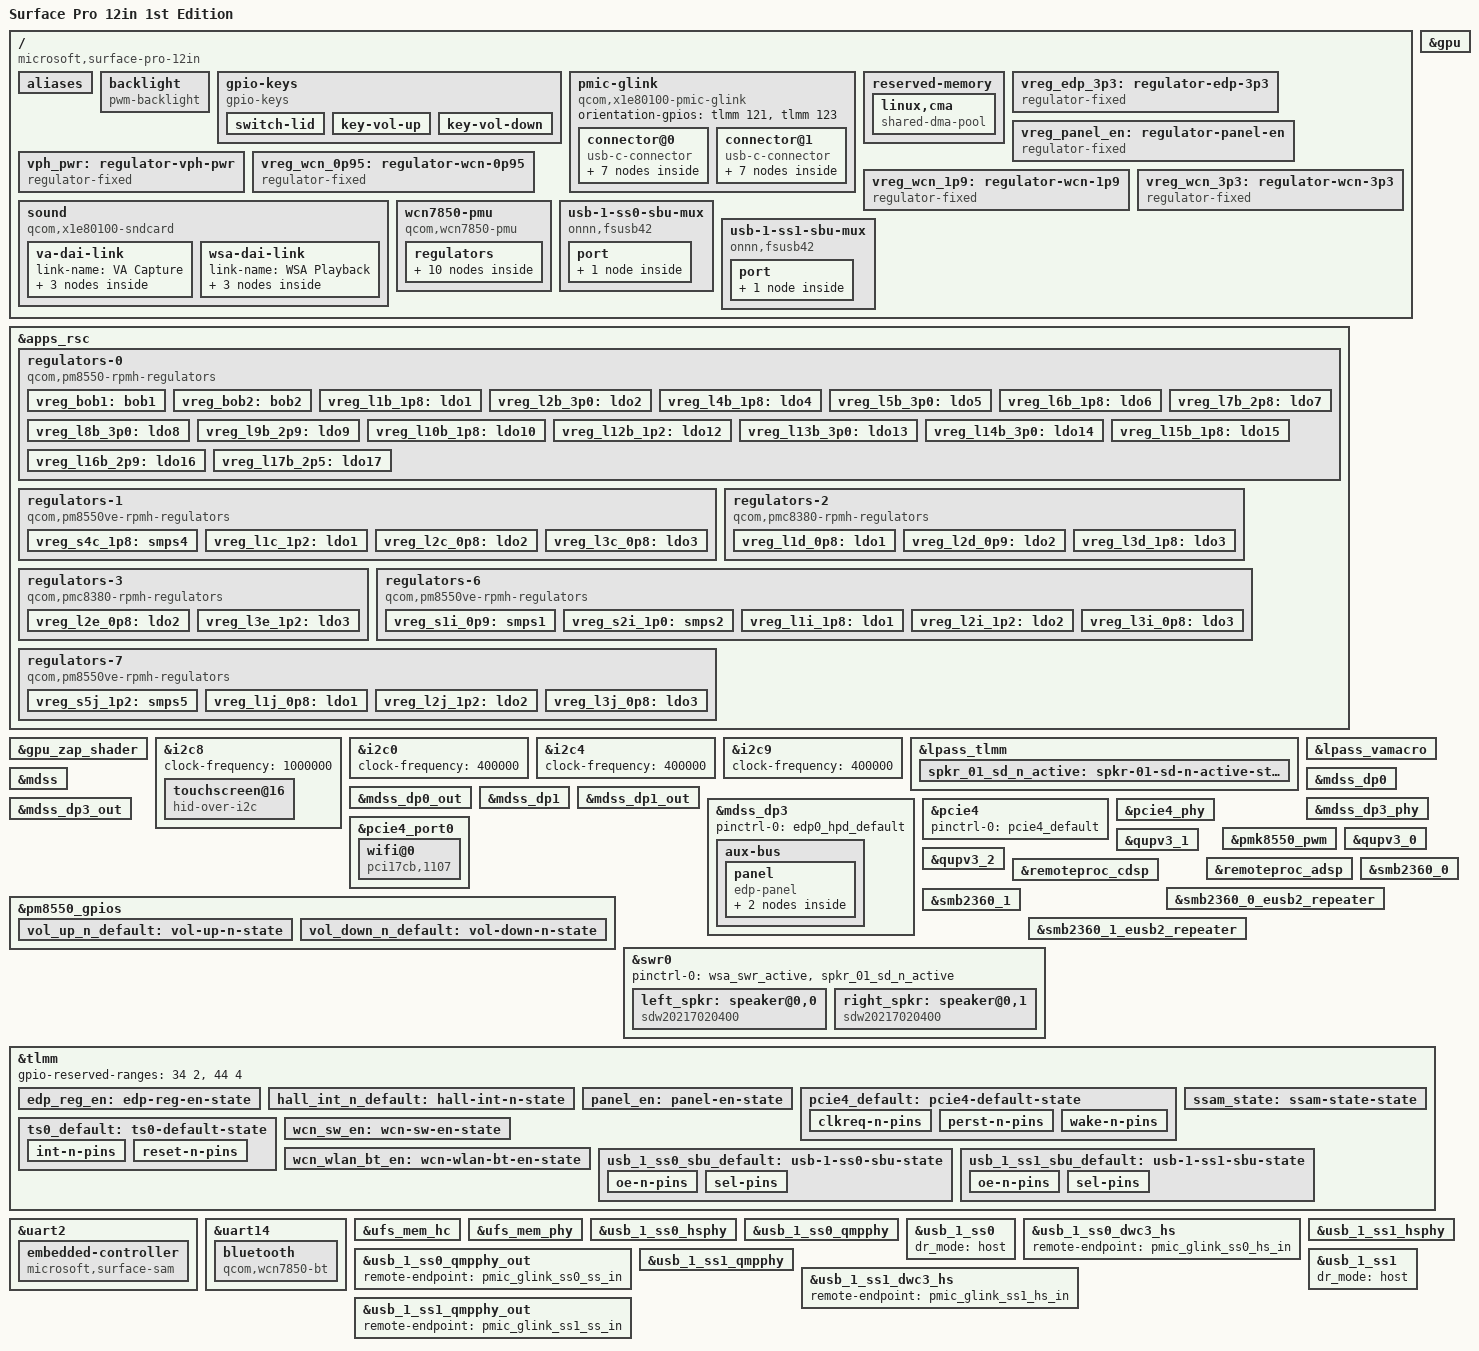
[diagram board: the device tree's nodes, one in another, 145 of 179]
// SPDX-License-Identifier: BSD-3-Clause
/*
 * Copyright (c) 2023 Qualcomm Innovation Center, Inc. All rights reserved.
 * Copyright (c) 2024, Linaro Limited
 * Copyright (c) 2025, Jens Glathe
 * Copyright (c) 2025, Harrison Vanderbyl
 */

/dts-v1/;

#include <dt-bindings/gpio/gpio.h>
#include <dt-bindings/input/gpio-keys.h>
#include <dt-bindings/input/input.h>
#include <dt-bindings/pinctrl/qcom,pmic-gpio.h>
#include <dt-bindings/regulator/qcom,rpmh-regulator.h>
#include <dt-bindings/clock/qcom,x1e80100-tcsr.h>

#include "purwa.dtsi"
#include "hamoa-pmics.dtsi"

/delete-node/ &pmc8380_6;
/delete-node/ &pmc8380_6_thermal;

/ {
	model = "Surface Pro 12in 1st Edition";
	compatible = "microsoft,surface-pro-12in", "qcom,x1p42100";
	chassis-type = "tablet";

	aliases {
		serial0 = &uart2;
		serial1 = &uart14;
	};

	backlight: backlight {
		compatible = "pwm-backlight";
		pwms = <&pmk8550_pwm 0 5000000>;

		power-supply = <&vreg_edp_3p3>;
	};

	gpio-keys {
		compatible = "gpio-keys";

		pinctrl-0 = <&hall_int_n_default>, <&vol_up_n_default>, <&vol_down_n_default>;
		pinctrl-names = "default";

		switch-lid {
			gpios = <&tlmm 2 GPIO_ACTIVE_LOW>;
			linux,input-type = <EV_SW>;
			linux,code = <SW_LID>;
			wakeup-source;
			wakeup-event-action = <EV_ACT_DEASSERTED>;
		};

		key-vol-up {
			gpios = <&pm8550_gpios 8 GPIO_ACTIVE_LOW>;
			linux,code = <KEY_VOLUMEUP>;
			debounce-interval = <15>;
			linux,can-disable;
			wakeup-source;
		};

		key-vol-down {
			gpios = <&pm8550_gpios 6 GPIO_ACTIVE_LOW>;
			linux,code = <KEY_VOLUMEDOWN>;
			debounce-interval = <15>;
			linux,can-disable;
			wakeup-source;
		};
	};

	pmic-glink {
		compatible = "qcom,x1e80100-pmic-glink",
			     "qcom,sm8550-pmic-glink",
			     "qcom,pmic-glink";
		orientation-gpios = <&tlmm 121 GPIO_ACTIVE_HIGH>,
				    <&tlmm 123 GPIO_ACTIVE_HIGH>;
		#address-cells = <1>;
		#size-cells = <0>;

		/* Right-side upper port */
		connector@0 {
			compatible = "usb-c-connector";
			reg = <0>;
			power-role = "dual";
			data-role = "dual";

			ports {
				#address-cells = <1>;
				#size-cells = <0>;

				port@0 {
					reg = <0>;

					pmic_glink_ss0_hs_in: endpoint {
						remote-endpoint = <&usb_1_ss0_dwc3_hs>;
					};
				};

				port@1 {
					reg = <1>;

					pmic_glink_ss0_ss_in: endpoint {
						remote-endpoint = <&usb_1_ss0_qmpphy_out>;
					};
				};

				port@2 {
					reg = <2>;

					pmic_glink_ss0_sbu: endpoint {
						remote-endpoint = <&usb_1_ss0_sbu_mux>;
					};
				};
			};
		};

		/* Right-side lower port */
		connector@1 {
			compatible = "usb-c-connector";
			reg = <1>;
			power-role = "dual";
			data-role = "dual";

			ports {
				#address-cells = <1>;
				#size-cells = <0>;

				port@0 {
					reg = <0>;

					pmic_glink_ss1_hs_in: endpoint {
						remote-endpoint = <&usb_1_ss1_dwc3_hs>;
					};
				};

				port@1 {
					reg = <1>;

					pmic_glink_ss1_ss_in: endpoint {
						remote-endpoint = <&usb_1_ss1_qmpphy_out>;
					};
				};

				port@2 {
					reg = <2>;

					pmic_glink_ss1_sbu: endpoint {
						remote-endpoint = <&usb_1_ss1_sbu_mux>;
					};
				};
			};
		};
	};

	reserved-memory {
		linux,cma {
			compatible = "shared-dma-pool";
			size = <0x0 0x20000000>;
			reusable;
			linux,cma-default;
		};
	};

	vreg_edp_3p3: regulator-edp-3p3 {
		compatible = "regulator-fixed";

		regulator-name = "VREG_EDP_3P3";
		regulator-min-microvolt = <3300000>;
		regulator-max-microvolt = <3300000>;

		gpio = <&tlmm 70 GPIO_ACTIVE_HIGH>;
		enable-active-high;

		pinctrl-0 = <&edp_reg_en>;
		pinctrl-names = "default";

		regulator-boot-on;
		vin-supply = <&vreg_panel_en>;
	};

	vreg_panel_en: regulator-panel-en {
		compatible = "regulator-fixed";

		regulator-name = "VREG_PANEL_EN";
		regulator-min-microvolt = <3300000>;
		regulator-max-microvolt = <3300000>;

		gpio = <&tlmm 29 GPIO_ACTIVE_HIGH>;
		enable-active-high;

		regulator-enable-ramp-delay = <150000>;

		pinctrl-0 = <&panel_en>;
		pinctrl-names = "default";

		regulator-boot-on;
	};

	vph_pwr: regulator-vph-pwr {
		compatible = "regulator-fixed";

		regulator-name = "vph_pwr";
		regulator-min-microvolt = <3700000>;
		regulator-max-microvolt = <3700000>;
	};

	vreg_wcn_0p95: regulator-wcn-0p95 {
		compatible = "regulator-fixed";

		regulator-name = "VREG_WCN_0P95";
		regulator-min-microvolt = <950000>;
		regulator-max-microvolt = <950000>;

		vin-supply = <&vreg_wcn_3p3>;
	};

	vreg_wcn_1p9: regulator-wcn-1p9 {
		compatible = "regulator-fixed";

		regulator-name = "VREG_WCN_1P9";
		regulator-min-microvolt = <1900000>;
		regulator-max-microvolt = <1900000>;

		vin-supply = <&vreg_wcn_3p3>;
	};

	vreg_wcn_3p3: regulator-wcn-3p3 {
		compatible = "regulator-fixed";

		regulator-name = "VREG_WCN_3P3";
		regulator-min-microvolt = <3300000>;
		regulator-max-microvolt = <3300000>;

		gpio = <&tlmm 214 GPIO_ACTIVE_HIGH>;
		enable-active-high;

		pinctrl-0 = <&wcn_sw_en>;
		pinctrl-names = "default";
	};

	sound {
		compatible = "qcom,x1e80100-sndcard";
		model = "X1P42100-Microsoft-Surface-Pro-12in";
		audio-routing = "SpkrLeft IN", "WSA WSA_SPK1 OUT",
				"SpkrRight IN", "WSA WSA_SPK2 OUT",
				"VA DMIC0", "vdd-micb",
				"VA DMIC1", "vdd-micb";

		va-dai-link {
			link-name = "VA Capture";

			codec {
				sound-dai = <&lpass_vamacro 0>;
			};

			cpu {
				sound-dai = <&q6apmbedai VA_CODEC_DMA_TX_0>;
			};

			platform {
				sound-dai = <&q6apm>;
			};
		};

		wsa-dai-link {
			link-name = "WSA Playback";

			codec {
				sound-dai = <&left_spkr>, <&right_spkr>,
					    <&swr0 0>, <&lpass_wsamacro 0>;
			};

			cpu {
				sound-dai = <&q6apmbedai WSA_CODEC_DMA_RX_0>;
			};

			platform {
				sound-dai = <&q6apm>;
			};
		};
	};

	wcn7850-pmu {
		compatible = "qcom,wcn7850-pmu";

		vdd-supply = <&vreg_wcn_0p95>;
		vddio-supply = <&vreg_l15b_1p8>;
		vddaon-supply = <&vreg_wcn_0p95>;
		vdddig-supply = <&vreg_wcn_0p95>;
		vddrfa1p2-supply = <&vreg_wcn_1p9>;
		vddrfa1p8-supply = <&vreg_wcn_1p9>;

		wlan-enable-gpios = <&tlmm 117 GPIO_ACTIVE_HIGH>;
		bt-enable-gpios = <&tlmm 116 GPIO_ACTIVE_HIGH>;

		pinctrl-0 = <&wcn_wlan_bt_en>;
		pinctrl-names = "default";

		regulators {
			vreg_pmu_rfa_cmn: ldo0 {
				regulator-name = "vreg_pmu_rfa_cmn";
			};

			vreg_pmu_aon_0p59: ldo1 {
				regulator-name = "vreg_pmu_aon_0p59";
			};

			vreg_pmu_wlcx_0p8: ldo2 {
				regulator-name = "vreg_pmu_wlcx_0p8";
			};

			vreg_pmu_wlmx_0p85: ldo3 {
				regulator-name = "vreg_pmu_wlmx_0p85";
			};

			vreg_pmu_btcmx_0p85: ldo4 {
				regulator-name = "vreg_pmu_btcmx_0p85";
			};

			vreg_pmu_rfa_0p8: ldo5 {
				regulator-name = "vreg_pmu_rfa_0p8";
			};

			vreg_pmu_rfa_1p2: ldo6 {
				regulator-name = "vreg_pmu_rfa_1p2";
			};

			vreg_pmu_rfa_1p8: ldo7 {
				regulator-name = "vreg_pmu_rfa_1p8";
			};

			vreg_pmu_pcie_0p9: ldo8 {
				regulator-name = "vreg_pmu_pcie_0p9";
			};

			vreg_pmu_pcie_1p8: ldo9 {
				regulator-name = "vreg_pmu_pcie_1p8";
			};
		};
	};

	usb-1-ss0-sbu-mux {
		compatible = "onnn,fsusb42", "gpio-sbu-mux";

		enable-gpios = <&tlmm 168 GPIO_ACTIVE_LOW>;
		select-gpios = <&tlmm 167 GPIO_ACTIVE_HIGH>;

		pinctrl-0 = <&usb_1_ss0_sbu_default>;
		pinctrl-names = "default";

		mode-switch;
		orientation-switch;

		port {
			usb_1_ss0_sbu_mux: endpoint {
				remote-endpoint = <&pmic_glink_ss0_sbu>;
			};
		};
	};

	usb-1-ss1-sbu-mux {
		compatible = "onnn,fsusb42", "gpio-sbu-mux";

		enable-gpios = <&tlmm 179 GPIO_ACTIVE_LOW>;
		select-gpios = <&tlmm 178 GPIO_ACTIVE_HIGH>;

		pinctrl-0 = <&usb_1_ss1_sbu_default>;
		pinctrl-names = "default";

		mode-switch;
		orientation-switch;

		port {
			usb_1_ss1_sbu_mux: endpoint {
				remote-endpoint = <&pmic_glink_ss1_sbu>;
			};
		};
	};
};

&apps_rsc {
	regulators-0 {
		compatible = "qcom,pm8550-rpmh-regulators";
		qcom,pmic-id = "b";

		vdd-bob1-supply = <&vph_pwr>;
		vdd-bob2-supply = <&vph_pwr>;
		vdd-l1-l4-l10-supply = <&vreg_s4c_1p8>;
		vdd-l2-l13-l14-supply = <&vreg_bob1>;
		vdd-l5-l16-supply = <&vreg_bob1>;
		vdd-l6-l7-supply = <&vreg_bob2>;
		vdd-l8-l9-supply = <&vreg_bob1>;
		vdd-l12-supply = <&vreg_s5j_1p2>;
		vdd-l15-supply = <&vreg_s4c_1p8>;
		vdd-l17-supply = <&vreg_bob2>;

		vreg_bob1: bob1 {
			regulator-name = "vreg_bob1";
			regulator-min-microvolt = <3008000>;
			regulator-max-microvolt = <3960000>;
			regulator-initial-mode = <RPMH_REGULATOR_MODE_HPM>;
		};

		vreg_bob2: bob2 {
			regulator-name = "vreg_bob2";
			regulator-min-microvolt = <2504000>;
			regulator-max-microvolt = <3008000>;
			regulator-initial-mode = <RPMH_REGULATOR_MODE_HPM>;
		};

		vreg_l1b_1p8: ldo1 {
			regulator-name = "vreg_l1b_1p8";
			regulator-min-microvolt = <1800000>;
			regulator-max-microvolt = <1800000>;
			regulator-initial-mode = <RPMH_REGULATOR_MODE_HPM>;
		};

		vreg_l2b_3p0: ldo2 {
			regulator-name = "vreg_l2b_3p0";
			regulator-min-microvolt = <3072000>;
			regulator-max-microvolt = <3100000>;
			regulator-initial-mode = <RPMH_REGULATOR_MODE_HPM>;
		};

		vreg_l4b_1p8: ldo4 {
			regulator-name = "vreg_l4b_1p8";
			regulator-min-microvolt = <1800000>;
			regulator-max-microvolt = <1800000>;
			regulator-initial-mode = <RPMH_REGULATOR_MODE_HPM>;
		};

		vreg_l5b_3p0: ldo5 {
			regulator-name = "vreg_l5b_3p0";
			regulator-min-microvolt = <3000000>;
			regulator-max-microvolt = <3000000>;
			regulator-initial-mode = <RPMH_REGULATOR_MODE_HPM>;
		};

		vreg_l6b_1p8: ldo6 {
			regulator-name = "vreg_l6b_1p8";
			regulator-min-microvolt = <1800000>;
			regulator-max-microvolt = <2960000>;
			regulator-initial-mode = <RPMH_REGULATOR_MODE_HPM>;
		};

		vreg_l7b_2p8: ldo7 {
			regulator-name = "vreg_l7b_2p8";
			regulator-min-microvolt = <2800000>;
			regulator-max-microvolt = <2800000>;
			regulator-initial-mode = <RPMH_REGULATOR_MODE_HPM>;
			regulator-always-on;
		};

		vreg_l8b_3p0: ldo8 {
			regulator-name = "vreg_l8b_3p0";
			regulator-min-microvolt = <3072000>;
			regulator-max-microvolt = <3072000>;
			regulator-initial-mode = <RPMH_REGULATOR_MODE_HPM>;
		};

		vreg_l9b_2p9: ldo9 {
			regulator-name = "vreg_l9b_2p9";
			regulator-min-microvolt = <2960000>;
			regulator-max-microvolt = <2960000>;
			regulator-initial-mode = <RPMH_REGULATOR_MODE_HPM>;
		};

		vreg_l10b_1p8: ldo10 {
			regulator-name = "vreg_l10b_1p8";
			regulator-min-microvolt = <1800000>;
			regulator-max-microvolt = <1800000>;
			regulator-initial-mode = <RPMH_REGULATOR_MODE_HPM>;
		};

		vreg_l12b_1p2: ldo12 {
			regulator-name = "vreg_l12b_1p2";
			regulator-min-microvolt = <1200000>;
			regulator-max-microvolt = <1200000>;
			regulator-initial-mode = <RPMH_REGULATOR_MODE_HPM>;
		};

		vreg_l13b_3p0: ldo13 {
			regulator-name = "vreg_l13b_3p0";
			regulator-min-microvolt = <3072000>;
			regulator-max-microvolt = <3100000>;
			regulator-initial-mode = <RPMH_REGULATOR_MODE_HPM>;
		};

		vreg_l14b_3p0: ldo14 {
			regulator-name = "vreg_l14b_3p0";
			regulator-min-microvolt = <3072000>;
			regulator-max-microvolt = <3072000>;
			regulator-initial-mode = <RPMH_REGULATOR_MODE_HPM>;
		};

		vreg_l15b_1p8: ldo15 {
			regulator-name = "vreg_l15b_1p8";
			regulator-min-microvolt = <1800000>;
			regulator-max-microvolt = <1800000>;
			regulator-initial-mode = <RPMH_REGULATOR_MODE_HPM>;
		};

		vreg_l16b_2p9: ldo16 {
			regulator-name = "vreg_l16b_2p9";
			regulator-min-microvolt = <2900000>;
			regulator-max-microvolt = <2912000>;
			regulator-initial-mode = <RPMH_REGULATOR_MODE_HPM>;
			regulator-allow-set-load;
			regulator-allowed-modes = <RPMH_REGULATOR_MODE_LPM
						   RPMH_REGULATOR_MODE_HPM>;
		};

		vreg_l17b_2p5: ldo17 {
			regulator-name = "vreg_l17b_2p5";
			regulator-min-microvolt = <2504000>;
			regulator-max-microvolt = <2504000>;
			regulator-initial-mode = <RPMH_REGULATOR_MODE_HPM>;
			regulator-allow-set-load;
			regulator-allowed-modes = <RPMH_REGULATOR_MODE_LPM
						   RPMH_REGULATOR_MODE_HPM>;
		};
	};

	regulators-1 {
		compatible = "qcom,pm8550ve-rpmh-regulators";
		qcom,pmic-id = "c";

		vdd-l1-supply = <&vreg_s5j_1p2>;
		vdd-s4-supply = <&vph_pwr>;

		vreg_s4c_1p8: smps4 {
			regulator-name = "vreg_s4c_1p8";
			regulator-min-microvolt = <1856000>;
			regulator-max-microvolt = <2000000>;
			regulator-initial-mode = <RPMH_REGULATOR_MODE_HPM>;
		};

		vreg_l1c_1p2: ldo1 {
			regulator-name = "vreg_l1c_1p2";
			regulator-min-microvolt = <1200000>;
			regulator-max-microvolt = <1200000>;
			regulator-initial-mode = <RPMH_REGULATOR_MODE_HPM>;
		};

		vreg_l2c_0p8: ldo2 {
			regulator-name = "vreg_l2c_0p8";
			regulator-min-microvolt = <880000>;
			regulator-max-microvolt = <920000>;
			regulator-initial-mode = <RPMH_REGULATOR_MODE_HPM>;
		};

		vreg_l3c_0p8: ldo3 {
			regulator-name = "vreg_l3c_0p8";
			regulator-min-microvolt = <880000>;
			regulator-max-microvolt = <920000>;
			regulator-initial-mode = <RPMH_REGULATOR_MODE_HPM>;
		};
	};

	regulators-2 {
		compatible = "qcom,pmc8380-rpmh-regulators";
		qcom,pmic-id = "d";

		vdd-l3-supply = <&vreg_s4c_1p8>;
		vdd-s1-supply = <&vph_pwr>;

		vreg_l1d_0p8: ldo1 {
			regulator-name = "vreg_l1d_0p8";
			regulator-min-microvolt = <880000>;
			regulator-max-microvolt = <920000>;
			regulator-initial-mode = <RPMH_REGULATOR_MODE_HPM>;
		};

		vreg_l2d_0p9: ldo2 {
			regulator-name = "vreg_l2d_0p9";
			regulator-min-microvolt = <912000>;
			regulator-max-microvolt = <920000>;
			regulator-initial-mode = <RPMH_REGULATOR_MODE_HPM>;
		};

		vreg_l3d_1p8: ldo3 {
			regulator-name = "vreg_l3d_1p8";
			regulator-min-microvolt = <1800000>;
			regulator-max-microvolt = <1800000>;
			regulator-initial-mode = <RPMH_REGULATOR_MODE_HPM>;
		};
	};

	regulators-3 {
		compatible = "qcom,pmc8380-rpmh-regulators";
		qcom,pmic-id = "e";

		vdd-l3-supply = <&vreg_s5j_1p2>;

		vreg_l2e_0p8: ldo2 {
			regulator-name = "vreg_l2e_0p8";
			regulator-min-microvolt = <880000>;
			regulator-max-microvolt = <880000>;
			regulator-initial-mode = <RPMH_REGULATOR_MODE_HPM>;
		};

		vreg_l3e_1p2: ldo3 {
			regulator-name = "vreg_l3e_1p2";
			regulator-min-microvolt = <1200000>;
			regulator-max-microvolt = <1200000>;
			regulator-initial-mode = <RPMH_REGULATOR_MODE_HPM>;
			regulator-allow-set-load;
			regulator-allowed-modes = <RPMH_REGULATOR_MODE_LPM
						   RPMH_REGULATOR_MODE_HPM>;
		};
	};

	regulators-6 {
		compatible = "qcom,pm8550ve-rpmh-regulators";
		qcom,pmic-id = "i";

		vdd-l1-supply = <&vreg_s4c_1p8>;
		vdd-l2-supply = <&vreg_s5j_1p2>;
		vdd-s1-supply = <&vph_pwr>;
		vdd-s2-supply = <&vph_pwr>;

		vreg_s1i_0p9: smps1 {
			regulator-name = "vreg_s1i_0p9";
			regulator-min-microvolt = <900000>;
			regulator-max-microvolt = <920000>;
			regulator-initial-mode = <RPMH_REGULATOR_MODE_HPM>;
		};

		vreg_s2i_1p0: smps2 {
			regulator-name = "vreg_s2i_1p0";
			regulator-min-microvolt = <1000000>;
			regulator-max-microvolt = <1100000>;
			regulator-initial-mode = <RPMH_REGULATOR_MODE_HPM>;
		};

		vreg_l1i_1p8: ldo1 {
			regulator-name = "vreg_l1i_1p8";
			regulator-min-microvolt = <1800000>;
			regulator-max-microvolt = <1800000>;
			regulator-initial-mode = <RPMH_REGULATOR_MODE_HPM>;
		};

		vreg_l2i_1p2: ldo2 {
			regulator-name = "vreg_l2i_1p2";
			regulator-min-microvolt = <1200000>;
			regulator-max-microvolt = <1200000>;
			regulator-initial-mode = <RPMH_REGULATOR_MODE_HPM>;
			regulator-allow-set-load;
			regulator-allowed-modes = <RPMH_REGULATOR_MODE_LPM
						   RPMH_REGULATOR_MODE_HPM>;
		};

		vreg_l3i_0p8: ldo3 {
			regulator-name = "vreg_l3i_0p8";
			regulator-min-microvolt = <880000>;
			regulator-max-microvolt = <880000>;
			regulator-initial-mode = <RPMH_REGULATOR_MODE_HPM>;
			regulator-allow-set-load;
			regulator-allowed-modes = <RPMH_REGULATOR_MODE_LPM
						   RPMH_REGULATOR_MODE_HPM>;
		};
	};

	regulators-7 {
		compatible = "qcom,pm8550ve-rpmh-regulators";
		qcom,pmic-id = "j";

		vdd-l2-supply = <&vreg_s5j_1p2>;
		vdd-s5-supply = <&vph_pwr>;

		vreg_s5j_1p2: smps5 {
			regulator-name = "vreg_s5j_1p2";
			regulator-min-microvolt = <1256000>;
			regulator-max-microvolt = <1304000>;
			regulator-initial-mode = <RPMH_REGULATOR_MODE_HPM>;
		};

		vreg_l1j_0p8: ldo1 {
			regulator-name = "vreg_l1j_0p8";
			regulator-min-microvolt = <880000>;
			regulator-max-microvolt = <920000>;
			regulator-initial-mode = <RPMH_REGULATOR_MODE_HPM>;
		};

		vreg_l2j_1p2: ldo2 {
			regulator-name = "vreg_l2j_1p2";
			regulator-min-microvolt = <1200000>;
			regulator-max-microvolt = <1256000>;
			regulator-initial-mode = <RPMH_REGULATOR_MODE_HPM>;
			regulator-allow-set-load;
			regulator-allowed-modes = <RPMH_REGULATOR_MODE_LPM
						   RPMH_REGULATOR_MODE_HPM>;
		};

		vreg_l3j_0p8: ldo3 {
			regulator-name = "vreg_l3j_0p8";
			regulator-min-microvolt = <880000>;
			regulator-max-microvolt = <880000>;
			regulator-initial-mode = <RPMH_REGULATOR_MODE_HPM>;
			regulator-allow-set-load;
			regulator-allowed-modes = <RPMH_REGULATOR_MODE_LPM
						   RPMH_REGULATOR_MODE_HPM>;
		};
	};
};

&gpu {
	status = "okay";
};

&gpu_zap_shader {
	firmware-name = "qcom/x1p42100/Microsoft/Surface12/qcdxkmsucpurwa.mbn";
};

&i2c8 {
	clock-frequency = <1000000>;

	status = "okay";

	touchscreen@16 {
		compatible = "hid-over-i2c";
		reg = <0x16>;

		hid-descr-addr = <0x1>;
		interrupts-extended = <&tlmm 38 IRQ_TYPE_LEVEL_LOW>;
		wakeup-source;

		vddl-supply = <&vreg_l15b_1p8>;

		pinctrl-0 = <&ts0_default>;
		pinctrl-names = "default";
	};
};

&i2c0 {
	clock-frequency = <400000>;

	status = "okay";
};

&i2c4 {
	clock-frequency = <400000>;

	status = "okay";

	/* MAX34417 @12 */
	/* MAX34417 @14 */
	/* MAX34417 @16 */
	/* MAX34417 @18 */
	/* MAX34417 @1a */
};

&i2c9 {
	clock-frequency = <400000>;

	status = "okay";

	/* NFC @28 Business 2109 sku only */
};

&lpass_tlmm {
	spkr_01_sd_n_active: spkr-01-sd-n-active-state {
		pins = "gpio12";
		function = "gpio";
		drive-strength = <2>;
		bias-disable;
		output-low;
	};
};

&lpass_vamacro {
	qcom,dmic-sample-rate = <4800000>;

	vdd-micb-supply = <&vreg_l1b_1p8>;

	pinctrl-0 = <&dmic01_default>;
	pinctrl-names = "default";
};

&mdss {
	status = "okay";
};

&mdss_dp0 {
	status = "okay";
};

&mdss_dp0_out {
	link-frequencies = /bits/ 64 <1620000000 2700000000 5400000000 8100000000>;
};

&mdss_dp1 {
	status = "okay";
};

&mdss_dp1_out {
	link-frequencies = /bits/ 64 <1620000000 2700000000 5400000000 8100000000>;
};

&mdss_dp3 {
	/delete-property/ #sound-dai-cells;

	pinctrl-0 = <&edp0_hpd_default>;
	pinctrl-names = "default";

	status = "okay";

	aux-bus {
		panel: panel {
			compatible = "edp-panel";

			backlight = <&backlight>;

			power-supply = <&vreg_edp_3p3>;

			port {
				edp_panel_in: endpoint {
					remote-endpoint = <&mdss_dp3_out>;
				};
			};
		};
	};
};

&mdss_dp3_out {
	data-lanes = <0 1 2 3>;
	link-frequencies = /bits/ 64 <1620000000 2700000000 5400000000 8100000000>;

	remote-endpoint = <&edp_panel_in>;
};

&mdss_dp3_phy {
	vdda-phy-supply = <&vreg_l3j_0p8>;
	vdda-pll-supply = <&vreg_l2j_1p2>;

	status = "okay";
};

&pcie4 {
	pinctrl-0 = <&pcie4_default>;
	pinctrl-names = "default";

	status = "okay";
};

&pcie4_phy {
	vdda-phy-supply = <&vreg_l3i_0p8>;
	vdda-pll-supply = <&vreg_l3e_1p2>;

	status = "okay";
};

&pcie4_port0 {
	reset-gpios = <&tlmm 146 GPIO_ACTIVE_LOW>;
	wake-gpios = <&tlmm 148 GPIO_ACTIVE_LOW>;

	wifi@0 {
		compatible = "pci17cb,1107";
		reg = <0x10000 0x0 0x0 0x0 0x0>;

		vddaon-supply = <&vreg_pmu_aon_0p59>;
		vddwlcx-supply = <&vreg_pmu_wlcx_0p8>;
		vddwlmx-supply = <&vreg_pmu_wlmx_0p85>;
		vddrfacmn-supply = <&vreg_pmu_rfa_cmn>;
		vddrfa0p8-supply = <&vreg_pmu_rfa_0p8>;
		vddrfa1p2-supply = <&vreg_pmu_rfa_1p2>;
		vddrfa1p8-supply = <&vreg_pmu_rfa_1p8>;
		vddpcie0p9-supply = <&vreg_pmu_pcie_0p9>;
		vddpcie1p8-supply = <&vreg_pmu_pcie_1p8>;
	};
};

&pm8550_gpios {
	vol_up_n_default: vol-up-n-state {
		pins = "gpio8";
		function = "normal";
		power-source = <1>;
		bias-pull-up;
		input-enable;
	};

	vol_down_n_default: vol-down-n-state {
		pins = "gpio6";
		function = "normal";
		power-source = <1>;
		bias-pull-up;
		input-enable;
	};
};

&pmk8550_pwm {
	status = "okay";
};

&qupv3_0 {
	status = "okay";
};

&qupv3_1 {
	status = "okay";
};

&qupv3_2 {
	status = "okay";
};

&remoteproc_adsp {
	firmware-name = "qcom/x1p42100/Microsoft/Surface12/qcadsp8380.mbn",
			"qcom/x1p42100/Microsoft/Surface12/adsp_dtbs.elf";

	status = "okay";
};

&remoteproc_cdsp {
	firmware-name = "qcom/x1p42100/Microsoft/Surface12/qccdsp8380.mbn",
			"qcom/x1p42100/Microsoft/Surface12/cdsp_dtbs.elf";

	status = "okay";
};

&smb2360_0 {
	status = "okay";
};

&smb2360_0_eusb2_repeater {
	vdd18-supply = <&vreg_l3d_1p8>;
	vdd3-supply = <&vreg_l2b_3p0>;
};

&smb2360_1 {
	status = "okay";
};

&smb2360_1_eusb2_repeater {
	vdd18-supply = <&vreg_l3d_1p8>;
	vdd3-supply = <&vreg_l14b_3p0>;
};

&swr0 {
	pinctrl-0 = <&wsa_swr_active>, <&spkr_01_sd_n_active>;
	pinctrl-names = "default";

	status = "okay";

	/* WSA8845, Left speaker */
	left_spkr: speaker@0,0 {
		compatible = "sdw20217020400";
		reg = <0 0>;
		reset-gpios = <&lpass_tlmm 12 GPIO_ACTIVE_LOW>;
		#sound-dai-cells = <0>;
		sound-name-prefix = "SpkrLeft";
		vdd-1p8-supply = <&vreg_l15b_1p8>;
		vdd-io-supply = <&vreg_l12b_1p2>;
		qcom,port-mapping = <1 2 3 7 10 13>;
	};

	/* WSA8845, Right speaker */
	right_spkr: speaker@0,1 {
		compatible = "sdw20217020400";
		reg = <0 1>;
		reset-gpios = <&lpass_tlmm 12 GPIO_ACTIVE_LOW>;
		#sound-dai-cells = <0>;
		sound-name-prefix = "SpkrRight";
		vdd-1p8-supply = <&vreg_l15b_1p8>;
		vdd-io-supply = <&vreg_l12b_1p2>;
		qcom,port-mapping = <4 5 6 7 11 13>;
	};
};

&tlmm {
	gpio-reserved-ranges = <34 2>, /* Unused */
			       <44 4>; /* SPI (TPM) */

	edp_reg_en: edp-reg-en-state {
		pins = "gpio70";
		function = "gpio";
		drive-strength = <2>;
		bias-disable;
	};

	hall_int_n_default: hall-int-n-state {
		pins = "gpio2";
		function = "gpio";
		bias-disable;
	};

	panel_en: panel-en-state {
		pins = "gpio29";
		function = "gpio";
		drive-strength = <2>;
		bias-disable;
	};

	pcie4_default: pcie4-default-state {
		clkreq-n-pins {
			pins = "gpio147";
			function = "pcie4_clk";
			drive-strength = <2>;
			bias-pull-up;
		};

		perst-n-pins {
			pins = "gpio146";
			function = "gpio";
			drive-strength = <2>;
			bias-disable;
		};

		wake-n-pins {
			pins = "gpio148";
			function = "gpio";
			drive-strength = <2>;
			bias-pull-up;
		};
	};

	ssam_state: ssam-state-state {
		pins = "gpio91";
		function = "gpio";
		bias-disable;
	};

	ts0_default: ts0-default-state {
		int-n-pins {
			pins = "gpio38";
			function = "gpio";
			bias-disable;
		};

		reset-n-pins {
			pins = "gpio48";
			function = "gpio";
			output-high;
			drive-strength = <16>;
		};
	};

	wcn_sw_en: wcn-sw-en-state {
		pins = "gpio214";
		function = "gpio";
		drive-strength = <2>;
		bias-disable;
	};

	wcn_wlan_bt_en: wcn-wlan-bt-en-state {
		pins = "gpio116", "gpio117";
		function = "gpio";
		drive-strength = <2>;
		bias-disable;
	};

	usb_1_ss0_sbu_default: usb-1-ss0-sbu-state {
		oe-n-pins {
			pins = "gpio168";
			function = "gpio";
			bias-disable;
			drive-strength = <2>;
		};

		sel-pins {
			pins = "gpio167";
			function = "gpio";
			bias-disable;
			drive-strength = <2>;
		};
	};

	usb_1_ss1_sbu_default: usb-1-ss1-sbu-state {
		oe-n-pins {
			pins = "gpio179";
			function = "gpio";
			bias-disable;
			drive-strength = <2>;
		};

		sel-pins {
			pins = "gpio178";
			function = "gpio";
			bias-disable;
			drive-strength = <2>;
		};
	};
};

&uart2 {
	status = "okay";

	embedded-controller {
		compatible = "microsoft,surface-sam";

		interrupts-extended = <&tlmm 91 IRQ_TYPE_EDGE_RISING>;

		current-speed = <4000000>;

		pinctrl-0 = <&ssam_state>;
		pinctrl-names = "default";
	};
};

&uart14 {
	status = "okay";

	bluetooth {
		compatible = "qcom,wcn7850-bt";
		max-speed = <3200000>;

		vddaon-supply = <&vreg_pmu_aon_0p59>;
		vddwlcx-supply = <&vreg_pmu_wlcx_0p8>;
		vddwlmx-supply = <&vreg_pmu_wlmx_0p85>;
		vddrfacmn-supply = <&vreg_pmu_rfa_cmn>;
		vddrfa0p8-supply = <&vreg_pmu_rfa_0p8>;
		vddrfa1p2-supply = <&vreg_pmu_rfa_1p2>;
		vddrfa1p8-supply = <&vreg_pmu_rfa_1p8>;
	};
};

&ufs_mem_hc {
	vcc-supply = <&vreg_l17b_2p5>;
	vcc-max-microamp = <800000>;
	vccq-supply = <&vreg_l2i_1p2>;
	vccq-max-microamp = <900000>;

	vdd-hba-supply = <&vreg_l3j_0p8>;

	status = "okay";
};

&ufs_mem_phy {
	status = "okay";

	vdda-phy-supply = <&vreg_l3i_0p8>;
	vdda-pll-supply = <&vreg_l3e_1p2>;
};

&usb_1_ss0_hsphy {
	vdd-supply = <&vreg_l3j_0p8>;
	vdda12-supply = <&vreg_l2j_1p2>;

	phys = <&smb2360_0_eusb2_repeater>;

	status = "okay";
};

&usb_1_ss0_qmpphy {
	vdda-phy-supply = <&vreg_l2j_1p2>;
	vdda-pll-supply = <&vreg_l1j_0p8>;

	status = "okay";
};

&usb_1_ss0 {
	dr_mode = "host";

	status = "okay";
};

&usb_1_ss0_dwc3_hs {
	remote-endpoint = <&pmic_glink_ss0_hs_in>;
};

&usb_1_ss0_qmpphy_out {
	remote-endpoint = <&pmic_glink_ss0_ss_in>;
};

&usb_1_ss1_hsphy {
	vdd-supply = <&vreg_l3j_0p8>;
	vdda12-supply = <&vreg_l2j_1p2>;

	phys = <&smb2360_1_eusb2_repeater>;

	status = "okay";
};

&usb_1_ss1_qmpphy {
	vdda-phy-supply = <&vreg_l2j_1p2>;
	vdda-pll-supply = <&vreg_l2d_0p9>;

	status = "okay";
};

&usb_1_ss1 {
	dr_mode = "host";

	status = "okay";
};

&usb_1_ss1_dwc3_hs {
	remote-endpoint = <&pmic_glink_ss1_hs_in>;
};

&usb_1_ss1_qmpphy_out {
	remote-endpoint = <&pmic_glink_ss1_ss_in>;
};
